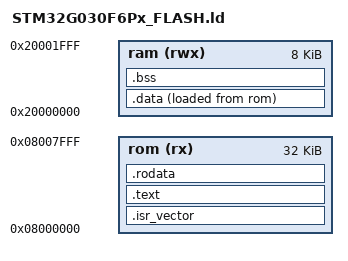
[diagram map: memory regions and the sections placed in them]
MEMORY {
    rom (rx)    : org = 0x08000000, len = 32k
    ram (rwx)   : org = 0x20000000, len = 8k
}

ENTRY(Reset_Handler)

SECTIONS {
    .isr_vector : {
        . = ALIGN(4);
        KEEP(*(.isr_vector))
        . = ALIGN(4);
    } > rom

    .text : {
        . = ALIGN(4);
        *(.text)
        *(.text*) 
        *(.glue_7)
        *(.glue_7t)
        . = ALIGN(4);
        _etext = .;
    } > rom

    .rodata : {
        . = ALIGN(4);
        *(.rodata)
        *(.rodata*)
        . = ALIGN(4);
    } > rom

    .data : {
        _sidata = LOADADDR(.data);
        . = ALIGN(4);
        _sdata = .;
        *(.data)
        *(.data*)
        . = ALIGN(4);
        _edata = .;
    } > ram AT > rom

    .bss : {
        . = ALIGN(4);
        _sbss = .;
        __bss_start__ = _sbss;
        *(.bss)
        *(.bss*)
        *(COMMON)
        . = ALIGN(4);
        _ebss = .;
        __bss_end__ = _ebss;
    } > ram

    _estack = ORIGIN(ram) + LENGTH(ram);
}
